# ADC_R_ADC_R_CFG_502C5000h register map
Vendor: Texas Instruments
Peripheral module from a debugger description file (folder AM263P).
Registers are 16-bit, read-only, reset values left out (the file's numbers can be read two ways) unless marked. A register's access mark holds for its fields unless they carry their own. Offsets are as the file gives them; lines under a group give offsets from that group; [hi:lo] are bit positions; {n}, {i} and the like mark numbered series; 'fields as' and 'values as' point back to an identical list; <NAME> marks a mode.

## ADC_R_CFG (part 1 of 2)
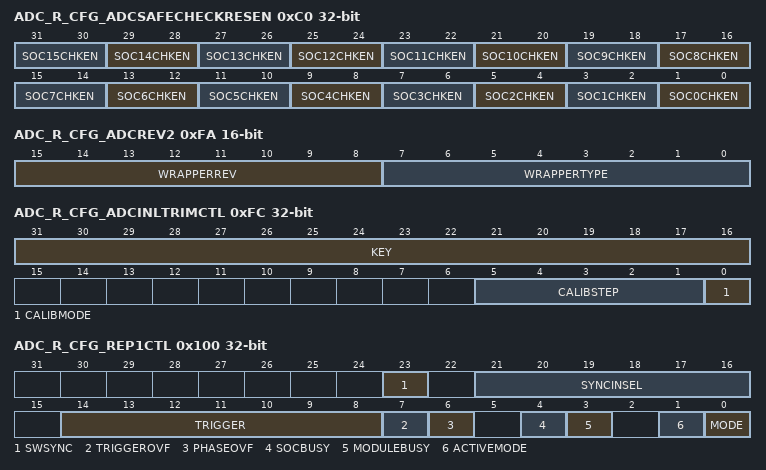
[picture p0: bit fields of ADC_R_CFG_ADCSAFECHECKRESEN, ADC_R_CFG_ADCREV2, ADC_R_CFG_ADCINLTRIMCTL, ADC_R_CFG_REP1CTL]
0xC0 ADC_R_CFG_ADCSAFECHECKRESEN 32-bit rw — ADC Safe Check Result Enable Register.
  [2n+1:2n] SOC{n}CHKEN (n=0..15) — Determine which result will be passed to the safety result checker. Only one of the raw ADC result, the PPB result, or the final PPB accumulated SUM can be passed on to the checker for each conversion. 00 No result passed to safety checker 01 ADCRESULT{n} passed to safety checker 10 PPB Result associated with SOC{n} passed to safety checker 11 PPB Sum associated with SOC{n} passed to safety chekcer Note: if multiple PPBs point to the same SOC, the highest numbered PPB will have priority to pass its result to the safety checker
0xDE ADC_R_CFG_ADCINTCYCLE rw — ADC Early Interrupt Generation Cycle.
  [15:0] DELAY — ADC Early Interrupt Generation Cycle Delay: Defines the delay from the fall edge of ADCSOC in terms of system clock cycles, for the interrupt to be generated.
0xFA ADC_R_CFG_ADCREV2 — ADC Wrapper Revision Register.
  [15:8] WRAPPERREV — ADC Revision. To allow documentation of differences between revisions. First version is labeled as00h
  [7:0] WRAPPERTYPE — ADC Wrapper Type. Always set to 4 for this ADC.
0xFC ADC_R_CFG_ADCINLTRIMCTL 32-bit rw — ADC Linearity Trim Control Register.
  [31:16] KEY — ADC Linearity Trim Control Write Key. Any write to this register must contain the value 0xA5A5 in these bit locations. If a write request attempts to load any other value into these bits, the write for the entire register is ignored. These bits always read back a zero.
  [5:1] CALIBSTEP — ADC Linearity Calibration Step. Defines which of the 24 steps of calibration is to be executed. Never set this bit field while the ADC SELFTRIM is in progress. The R-M-W operation could unintentionally set the CALIBMODE bit again.
  [0] CALIBMODE — ADC Linearity Calibration Mode.
0x100 ADC_R_CFG_REP1CTL 32-bit access not given — ADC Trigger Repeater 1 Control Register.
  [23] SWSYNC — Trigger repeater 1 software force sync. On a sync. event, all registers in repeater 1 are reset to a ready and waiting state. Values of NSEL, PHASE, and MODE are preserved. Note: SOCs associated with repeater 1 are not cleared. (access R/W1TS)
  [21:16] SYNCINSEL rw — Trigger repeater 1 sync. input select. On a sync. event, all registers in repeater 1 are reset to a ready and waiting state. Values of NSEL, PHASE, and MODE are preserved. Note: SOCs associated with repeater 1 are not cleared.
  [14:8] TRIGGER rw — ADC Trigger Repeater 1 Trigger Select. Selects the trigger to modify via oversampling or undersampling. 00h REPTRIG0 - Software only 01h REPTRIG1 - RTI0 Timer 02h REPTRIG2 - RTI1 Timer 03h REPTRIG3 - RTI2 Timer 04h REPTRIG4 - RTI3 Timer 05h REPTRIG5 - InputXBAR.Out[5] 06h REPTRIG6 - spare 07h REPTRIG7 - spare 08h REPTRIG8 - EPWM0, ADCSOCA 09h REPTRIG9 - EPWM0, ADCSOCB 0Ah REPTRIG10 - EPWM1, ADCSOCA 0Bh REPTRIG11 - EPWM1, ADCSOCB 0Ch REPTRIG12 - EPWM2, ADCSOCA 0Dh REPTRIG13 - EPWM2, ADCSOCB 0Eh REPTRIG14 - EPWM3, ADCSOCA 0Fh REPTRIG15 - EPWM3, ADCSOCB .... EPWM4 to EPWM27 40h REPTRIG64 - EPWM28, ADCSOCA 41h REPTRIG65 - EPWM28, ADCSOCB 42h REPTRIG66 - EPWM29, ADCSOCA 43h REPTRIG67 - EPWM29, ADCSOCB 44h REPTRIG68 - EPWM30, ADCSOCA 45h REPTRIG69 - EPWM30, ADCSOCB 46h REPTRIG70 - EPWM31, ADCSOCA 47h REPTRIG71 - EPWM31, ADCSOCB 48h REPTRIG72 - ECAP0, TRIGOUT .... ECAP1 to ECAP8 51h REPTRIG81 - ECAP9, TRIGOUT 52h REPTRIG82 - ECAP10, TRIGOUT .... 57h REPTRIG73 - ECAP15, TRIGOUT 58h REPTRIG1 - RTI4 Timer 59h REPTRIG1 - RTI5 Timer 5Ah REPTRIG1 - RTI6 Timer 5Bh REPTRIG1 - RTI7 Timer .... 7Fh - Reserved
  [7] TRIGGEROVF — ADC Trigger Repeater 1 Oversampled Trigger Overflow. Indicates that a trigger was dropped because a trigger arrived while the repeater was still generating repeated oversampled triggers [NCOUNT was not 0 or SOCs associated with Repeater 1 were still pending]. Writing a 1 will clear this flag. Note: This flag won't be set in undersampling mode or when NSEL = 0; if a trigger arrives before the previous SOCs have completed, the trigger will be passed and the overflow flags of the SOCs that were still pending will be set. Note: If software sets the clear bit on the same cycle that hardware is trying to set the flag bit, then hardware has priority and the overflow bit will not be set (access R/W1TC)
  [6] PHASEOVF — ADC Trigger Repeater 1 Phase Delay Overflow. Indicates that a trigger was dropped because a trigger arrived when the phase delay logic was still waiting to send the delayed trigger [PHASECOUNT was not 0]. Writing a 1 will clear this flag. Note: If software sets the clear bit on the same cycle that hardware is trying to set the flag bit, then hardware has priority and the overflow bit will not be set (access R/W1TC)
  [4] SOCBUSY ro — ADC Trigger Repeater 1 Associated SOCs Busy indicator. In oversampling mode: 0 = no SOCs associated with this repeater are pending 1 = SOCs associated with this repeater are still pending The next repeated trigger to the ADC in oversampling mode will not occur until SPREADCOUNT is 0 [minimum time is complete] and REP1CTL.BUSY = 0 [SOCs associated with trigger repeater 1 are no longer pending]. Note: If the ADC is in burstmode and the BURSTTRIG is Repeater 1, then all round-robin SOCs are considered associated with this repeater and the repeater will not re-trigger until there are no pending round-robin SOCs [in addition to any associated pending high-priority SOCs].
  [3] MODULEBUSY ro — ADC Trigger Repeater 1 Module Busy indicator. In oversampling mode: 0 = Repeater 1 is idle and can accept a new repeated trigger in oversampling mode 1 = Repeater 1 still has repeated triggers remaining [NCOUNT ' 0] or associated SOCs are still pending [SOCBUSY is 1] If a new oversampled trigger is received while the module is still busy, the TRIGGEROVF bit will be set and the trigger will be ignored.
  [1] ACTIVEMODE ro — When a trigger is recived in oversampling or undersampling mode the value of MODE is copied to ACTIVEMODE. ACTIVEMODE determines if the repeater will repeat of filter triggers. Changes to MODE while the repeater is working therefore won't cause any changes in functionality until the module becomes idle and then a new trigger is received. 0 = module is oversampling 1 = module is undersampling
  [0] MODE rw — ADC trigger repeater 1 mode selection. Select either oversampling or undersampling mode. In oversampling mode, when the trigger selected by REP1CTL.TRIGSEL is received, the repeater will repeat the trigger REP1N.NSEL + 1 times. In undersampling mode, when the trigger selected by REP1CTL.TRIGSEL is received the first time, the repeater will pass the trigger through. The next REP1N.NSEL triggers will be ignored. 0 = oversampling 1 = undersampling
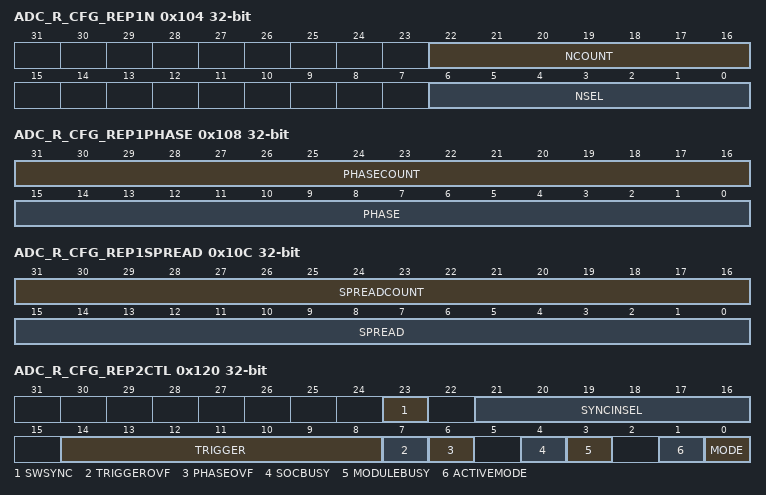
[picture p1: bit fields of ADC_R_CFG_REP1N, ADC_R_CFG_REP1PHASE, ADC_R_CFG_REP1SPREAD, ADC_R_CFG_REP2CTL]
0x104 ADC_R_CFG_REP1N 32-bit access per field — ADC Trigger Repeater 1 N Select Register.
  [22:16] NCOUNT ro — ADC trigger repeater 1 trigger count. In oversampling mode, indicates the number of triggers remaining to be generated. If a trigger is received corresponding to REP1CTL.TRIGSEL while NCOUNT is not 0 [the repeater is still busy generating the repeated triggers] then the trigger will be ignored and REP1CTL.TRIGOVF will be set to 1. In undersampling mode, indicates the number of triggers remaining to be supressed.
  [6:0] NSEL rw — ADC Trigger Repeater 1 selection of number of triggers. In oversampling mode, selects the number of repeated triggers. For each trigger received corresponding to REP1CTL.TRIGSEL, NSEL + 1 triggers will be generated. 0 = 1 trigger is generated [pass-through] 1 = 2 triggers are generated 2 = 3 triggers are generated ... 127 = 128 triggers are generated In undersampling mode, selects the number triggers to be supressed. 1 out NSEL + 1 triggers received corresponding to REP1CTL.TRIGSEL will be passed through [the first trigger will be passed through and the subsequent NSEL triggers will be supressed]. 0 = all triggers are passed 1 = 1 out of 2 triggers are passed 2 = 1 out of 3 triggers are passed ... 127 = 1 out of 128 triggers are passed
0x108 ADC_R_CFG_REP1PHASE 32-bit access per field — ADC Trigger Repeater 1 Phase Select Register.
  [31:16] PHASECOUNT ro — ADC trigger repeater 1 phase delay status. When the trigger selected by REP1CTL.TRIGSEL is received, this register will start counting down from PHASECOUNT until the counter reaches 0, at which point the trigger will be passed on to the repeater re-trigger logic. If the trigger selected by REP1CTL.TRIGSEL is recieved when PHASECOUNT is not 0 [the phase delay logic is busy from the previous trigger] then the new trigger will be ignored and REP1CTL.PHASEOVF will be set to 1.
  [15:0] PHASE rw — ADC trigger repeater 1 phase delay configuration. Defines the number of SYSCLKs to delay the selected trigger before passing it on to the re-triggering logic. 0 = trigger is passed through without delay 1 = trigger is delayed by 1 SYSCLK 2 = trigger is delayed by 2 SYSCLKs ... 65535 = trigger is delayed by 65535 SYSCLKs
0x10C ADC_R_CFG_REP1SPREAD 32-bit access per field — ADC Trigger Repeater 1 Spread Select Register.
  [31:16] SPREADCOUNT ro — ADC trigger repeater 1 spread status. When a trigger is sent to the ADC in oversampling mode, this register will start counting down from SPREAD until SPREADCOUNT equals 0. The next repeated trigger to the ADC in oversampling mode will not occur until SPREADCOUNT is 0 [minimum time is complete] and REP1CTL.BUSY = 0 [SOCs associated with trigger repeater 1 are no longer pending].
  [15:0] SPREAD rw — ADC trigger repeater 1 spread delay configuration. In oversampling mode, defines the minimum number of SYSCLKs to wait before creating the next repeated trigger to the ADC. If SPREAD is less than the time needed for all SOCs associated with repeater 1 to sample and convert, then the repeater will generate triggers as fast as the ADC can convert the associated conversions. If SPREAD is greater than the time needed for all SOCs associated with repeater 1 to sample and convert, then repeated triggers to the ADC will be SPREAD SYSCLK cycles apart. 0 = oversampled repeated triggers occur as fast as the ADC can sample and convert associated SOCs 1 = time between repeated triggers is at least 1 SYSCLKs 2 = time between repeated triggers is at least 2 SYSCLKs ... 65535 = time between repeated triggers is at least 65535 SYSCLKs
0x110 ADC_R_CFG_REP1FRC access not given — ADC Trigger Repeater 1 Software Force Register.
  [0] SWFRC — Write 1 to force a trigger to repeat block 1 input regardless of the value of TRIGGER. Always reads 0. (access R/W1TS)
0x120 ADC_R_CFG_REP2CTL 32-bit access not given — ADC Trigger Repeater 2 Control Register.
  [23] SWSYNC — Trigger repeater 2 software force sync. On a sync. event, all registers in repeater 2 are reset to a ready and waiting state. Values of NSEL, PHASE, and MODE are preserved. Note: SOCs associated with repeater 2 are not cleared. (access R/W1TS)
  [21:16] SYNCINSEL rw — Trigger repeater 2 sync. input select. On a sync. event, all registers in repeater 2 are reset to a ready and waiting state. Values of NSEL, PHASE, and MODE are preserved. Note: SOCs associated with repeater 2 are not cleared.
  [14:8] TRIGGER rw — ADC Trigger Repeater 2 Trigger Select. Selects the trigger to modify via oversampling or undersampling. 00h REPTRIG0 - Software only 01h REPTRIG1 - RTI0 Timer 02h REPTRIG2 - RTI1 Timer 03h REPTRIG3 - RTI2 Timer 04h REPTRIG4 - RTI3 Timer 05h REPTRIG5 - InputXBAR.Out[5] 06h REPTRIG6 - spare 07h REPTRIG7 - spare 08h REPTRIG8 - EPWM0, ADCSOCA 09h REPTRIG9 - EPWM0, ADCSOCB 0Ah REPTRIG10 - EPWM1, ADCSOCA 0Bh REPTRIG11 - EPWM1, ADCSOCB 0Ch REPTRIG12 - EPWM2, ADCSOCA 0Dh REPTRIG13 - EPWM2, ADCSOCB 0Eh REPTRIG14 - EPWM3, ADCSOCA 0Fh REPTRIG15 - EPWM3, ADCSOCB .... EPWM4 to EPWM27 40h REPTRIG64 - EPWM28, ADCSOCA 41h REPTRIG65 - EPWM28, ADCSOCB 42h REPTRIG66 - EPWM29, ADCSOCA 43h REPTRIG67 - EPWM29, ADCSOCB 44h REPTRIG68 - EPWM30, ADCSOCA 45h REPTRIG69 - EPWM30, ADCSOCB 46h REPTRIG70 - EPWM31, ADCSOCA 47h REPTRIG71 - EPWM31, ADCSOCB 48h REPTRIG72 - ECAP0, TRIGOUT .... ECAP1 to ECAP8 51h REPTRIG81 - ECAP9, TRIGOUT 52h REPTRIG82 - ECAP10, TRIGOUT .... 57h REPTRIG73 - ECAP15, TRIGOUT 58h REPTRIG1 - RTI4 Timer 59h REPTRIG1 - RTI5 Timer 5Ah REPTRIG1 - RTI6 Timer 5Bh REPTRIG1 - RTI7 Timer .... 64h- 7Fh - Reserved
  [7] TRIGGEROVF — ADC Trigger Repeater 2 Oversampled Trigger Overflow. Indicates that a trigger was dropped because a trigger arrived while the repeater was still generating repeated oversampled triggers [NCOUNT was not 0 or SOCs associated with Repeater 2 were still pending]. Writing a 1 will clear this flag. Note: This flag won't be set in undersampling mode or when NSEL = 0; if a trigger arrives before the previous SOCs have completed, the trigger will be passed and the overflow flags of the SOCs that were still pending will be set. Note: If software sets the clear bit on the same cycle that hardware is trying to set the flag bit, then hardware has priority and the overflow bit will not be set (access R/W1TC)
  [6] PHASEOVF — ADC Trigger Repeater 2 Phase Delay Overflow. Indicates that a trigger was dropped because a trigger arrived when the phase delay logic was still waiting to send the delayed trigger [PHASECOUNT was not 0]. Writing a 1 will clear this flag. Note: If software sets the clear bit on the same cycle that hardware is trying to set the flag bit, then hardware has priority and the overflow bit will not be set (access R/W1TC)
  [4] SOCBUSY ro — ADC Trigger Repeater 2 Associated SOCs Busy indicator. In oversampling mode: 0 = no SOCs associated with this repeater are pending 1 = SOCs associated with this repeater are still pending The next repeated trigger to the ADC in oversampling mode will not occur until SPREADCOUNT is 0 [minimum time is complete] and REP2CTL.BUSY = 0 [SOCs associated with trigger repeater 2 are no longer pending]. Note: If the ADC is in burstmode and the BURSTTRIG is Repeater 2, then all round-robin SOCs are considered associated with this repeater and the repeater will not re-trigger until there are no pending round-robin SOCs [in addition to any associated pending high-priority SOCs].
  [3] MODULEBUSY ro — ADC Trigger Repeater 2 Module Busy indicator. In oversampling mode: 0 = Repeater 2 is idle and can accept a new repeated trigger in oversampling mode 1 = Repeater 2 still has repeated triggers remaining [NCOUNT ' 0] or associated SOCs are still pending [SOCBUSY is 1] If a new oversampled trigger is received while the module is still busy, the TRIGGEROVF bit will be set and the trigger will be ignored.
  [1] ACTIVEMODE ro — When a trigger is recived in oversampling or undersampling mode the value of MODE is copied to ACTIVEMODE. ACTIVEMODE determines if the repeater will repeat of filter triggers. Changes to MODE while the repeater is working therefore won't cause any changes in functionality until the module becomes idle and then a new trigger is received. 0 = module is oversampling 1 = module is undersampling
  [0] MODE rw — ADC trigger repeater 2 mode selection. Select either oversampling or undersampling mode. In oversampling mode, when the trigger selected by REP2CTL.TRIGSEL is received, the repeater will repeat the trigger REP2N.NSEL + 1 times. In undersampling mode, when the trigger selected by REP2CTL.TRIGSEL is received the first time, the repeater will pass the trigger through. The next REP2N.NSEL triggers will be ignored. 0 = oversampling 1 = undersampling
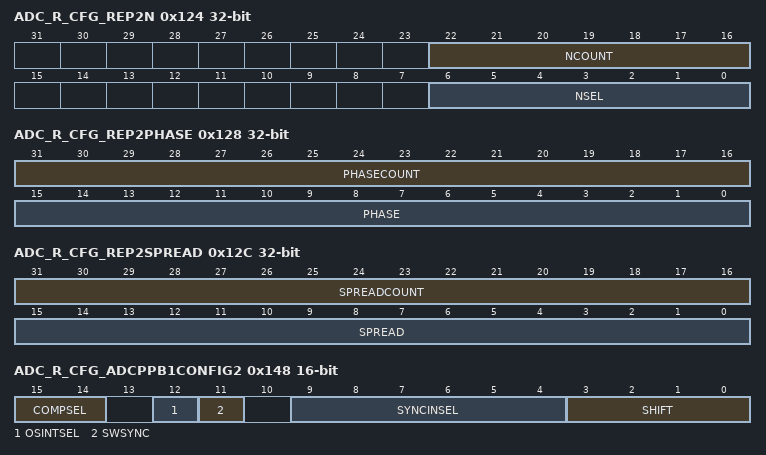
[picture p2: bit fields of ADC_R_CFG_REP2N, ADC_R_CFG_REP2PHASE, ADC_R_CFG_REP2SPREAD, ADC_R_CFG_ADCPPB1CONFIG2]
0x124 ADC_R_CFG_REP2N 32-bit access per field — ADC Trigger Repeater 2 N Select Register.
  [22:16] NCOUNT ro — ADC trigger repeater 2 trigger count. In oversampling mode, indicates the number of triggers remaining to be generated. If a trigger is received corresponding to REP2CTL.TRIGSEL while NCOUNT is not 0 [the repeater is still busy generating the repeated triggers] then the trigger will be ignored and REP2CTL.TRIGOVF will be set to 1. In undersampling mode, indicates the number of triggers remaining to be supressed.
  [6:0] NSEL rw — ADC Trigger Repeater 2 selection of number of triggers. In oversampling mode, selects the number of repeated triggers. For each trigger received corresponding to REP2CTL.TRIGSEL, NSEL + 1 triggers will be generated. 0 = 1 trigger is generated [pass-through] 1 = 2 triggers are generated 2 = 3 triggers are generated ... 127 = 128 triggers are generated In undersampling mode, selects the number triggers to be supressed. 1 out NSEL + 1 triggers received corresponding to REP2CTL.TRIGSEL will be passed through [the first trigger will be passed through and the subsequent NSEL triggers will be supressed]. 0 = all triggers are passed 1 = 1 out of 2 triggers are passed 2 = 1 out of 3 triggers are passed ... 127 = 1 out of 128 triggers are passed
0x128 ADC_R_CFG_REP2PHASE 32-bit access per field — ADC Trigger Repeater 2 Phase Select Register.
  [31:16] PHASECOUNT ro — ADC trigger repeater 2 phase delay status. When the trigger selected by REP2CTL.TRIGSEL is received, this register will start counting down from PHASECOUNT until the counter reaches 0, at which point the trigger will be passed on to the repeater re-trigger logic. If the trigger selected by REP2CTL.TRIGSEL is recieved when PHASECOUNT is not 0 [the phase delay logic is busy from the previous trigger] then the new trigger will be ignored and REP2CTL.PHASEOVF will be set to 1.
  [15:0] PHASE rw — ADC trigger repeater 2 phase delay configuration. Defines the number of SYSCLKs to delay the selected trigger before passing it on to the re-triggering logic. 0 = trigger is passed through without delay 1 = trigger is delayed by 1 SYSCLK 2 = trigger is delayed by 2 SYSCLKs ... 65535 = trigger is delayed by 65535 SYSCLKs
0x12C ADC_R_CFG_REP2SPREAD 32-bit access per field — ADC Trigger Repeater 2 Spread Select Register.
  [31:16] SPREADCOUNT ro — ADC trigger repeater 2 spread status. When a trigger is sent to the ADC in oversampling mode, this register will start counting down from SPREAD until SPREADCOUNT equals 0. The next repeated trigger to the ADC in oversampling mode will not occur until SPREADCOUNT is 0 [minimum time is complete] and REP2CTL.BUSY = 0 [SOCs associated with trigger repeater 2 are no longer pending].
  [15:0] SPREAD rw — ADC trigger repeater 2 spread delay configuration. In oversampling mode, defines the minimum number of SYSCLKs to wait before creating the next repeated trigger to the ADC. If SPREAD is less than the time needed for all SOCs associated with repeater 2 to sample and convert, then the repeater will generate triggers as fast as the ADC can convert the associated conversions. If SPREAD is greater than the time needed for all SOCs associated with repeater 2 to sample and convert, then repeated triggers to the ADC will be SPREAD SYSCLK cycles apart. 0 = oversampled repeated triggers occur as fast as the ADC can sample and convert associated SOCs 1 = time between repeated triggers is at least 1 SYSCLKs 2 = time between repeated triggers is at least 2 SYSCLKs ... 65535 = time between repeated triggers is at least 65535 SYSCLKs
0x130 ADC_R_CFG_REP2FRC access not given — ADC Trigger Repeater 2 Software Force Register.
  [0] SWFRC — Write 1 to force a trigger to repeat block 2 input regardless of the value of TRIGGER. Always reads 0. (access R/W1TS)
{0x10C+0x34*i} ADC_R_CFG_ADCPPB{i}LIMIT rw (i=1..4) — ADC PPB{i}Conversion Count Limit Register.
  [9:0] LIMIT — Post Processing Block {i} Oversampling Limit. Defines the number of conversions to accumulate before PSUM is automatically loaded into SUM. To prevent PSUM from overflowing, do not write a value larger than 128 when the ADC is operating in 16-bit mode.
0x144 ADC_R_CFG_ADCPPBP1PCOUNT — ADC PPB1 Partial Conversion Count Register.
  [9:0] PCOUNT — Post Processing Block 1 Oversampling Partial Count. Each time a new result propagates through the PPB signal chain and accumulates into ADCPPB1PSUM this register is incremented by 1. This register is reset when either a count-match event occurs [PCOUNT = LIMIT] or PPB1 receives a sync. event. This result is available 1 SYSCLK cycle after the associated ADCPPB1RESULT is available. This will be 2 SYSCLK cycles after the associated ADCRESULT is available, unless multiple PPBs point to the same SOC [refer to the ADCPPB1RESULT timing information].
0x148 ADC_R_CFG_ADCPPB1CONFIG2 access not given — ADC PPB1 Sum Shift Register.
  [15:14] COMPSEL rw — Post Processing Block 1 Compare Source Select. This field determines whether ADCPPB1RESULT, ADCPPB1PSUM, or ADCPPB1SUM is used for the zero-crossing detect logic and threshold compare. 00 = ADCPPB1RESULT is used for compare logic 01 = ADCPPB1PSUM is used for compare logic 10 = ADCPPB1SUM is used for compare logic 11 = Reserved Note: when ADCPPB1PSUM is selected as the compare source and when a LIMIT match occurs [ADCPPB1LIMIT equals ADCPPB1COUNT] the ADCPPB1PSUM register will be cleared and the final sum will be loaded into ADCPPB1SUM. For this sample, the final sum, ADCPPB1SUM will be used for the compariosn instead of ADCPPB1PSUM.
  [12] OSINTSEL rw — Post Processing Block 1 Interrupt Source Select. OSINT1 can be used to trigger an ADC interrupt [ADCINT1 through ADCINT4] via selection in the ADCINT1N2 or ADCINT3N4. This selection determines if a sync. event can trigger OSINT1 in addition to a PCOUNT = LIMIT event. 0 = OSINT1 will be generated from PCOUNT = LIMIT only 1 = OSTIN1 will be generated form PCOUNT = LIMIT or a sync. event. Note: If a SYNC event would cause an OSINT one cycle after OSINT would have been cause by PCOUNT = LIMIT match, then the second OSINT is ignored.
  [11] SWSYNC — PPB 1 software force sync. On a sync. event, all partial registers transfer to the final registers and are then reset. Note: In the case where the software force occurs at the same time that a new sample is added to the PSUM and the PSUM is being used for a high or low limit compare, then the comparison will not occur. (access R/W1TS)
  [9:4] SYNCINSEL rw — PPB 1 sync. input select. On a sync. event, all partial registers transfer to the final registers and are then reset. Refer to SOC spec for details
  [3:0] SHIFT rw — Post Processing Block 1 right shift. Defines the number of bits to right shift PSUM before loading into the final SUM. 0 : no right shift 1 : SUM = PSUM '' 1 2 : SUM = PSUM '' 2 ... 10 : SUM = PSUM '' 10 11 -15 : Reserved
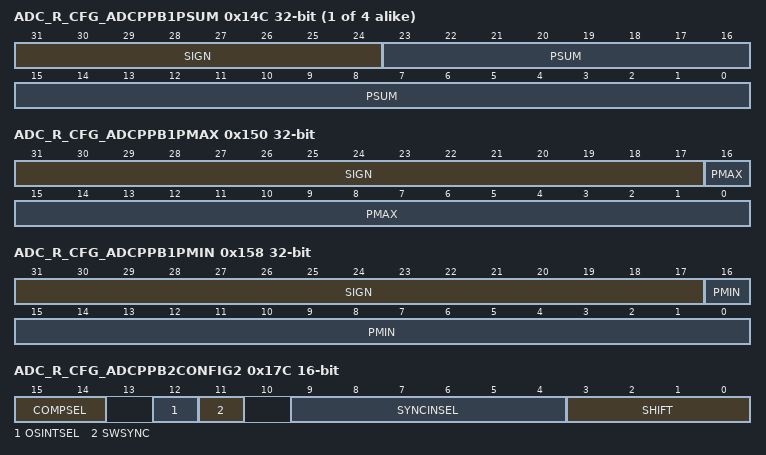
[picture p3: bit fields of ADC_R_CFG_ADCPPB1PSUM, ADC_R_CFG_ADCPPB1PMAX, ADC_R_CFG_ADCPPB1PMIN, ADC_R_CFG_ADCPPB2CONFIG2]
{0x118+0x34*i} ADC_R_CFG_ADCPPB{i}PSUM 32-bit (i=1..4) — ADC PPB{i} Partial Sum Register.
  [31:24] SIGN — Sign Extended Bits. These bits reflect the same value as bit 23.
  [23:0] PSUM — Post Processing Block {i} Oversampling Partial Sum. Each time a new result propagates through the PPB signal chain and latches into ADCPPB{i}RESULT the result is subsequently accumulated into this register. This register is reset when either a count-match event occurs [PCOUNT = LIMIT] or PPB{i} receives a sync. event. This result is available 1 SYSCLK cycle after the associated ADCPPB{i}RESULT is available. This will be 2 SYSCLK cycles after the associated ADCRESULT is available, unless multiple PPBs point to the same SOC. In the case of multiple PPBs associated with the same SOC, the lowest numbered PPB's result will be availble 2 SYSCLK cycle after the associated ADCRESULT and subsequent results [in order from lowest numbered PPB to highest] will each become available every 2-3 SYSCLK cycles [refer to the TRM for detailed timing information].
0x150 ADC_R_CFG_ADCPPB1PMAX 32-bit — ADC PPB1 Partial Max Register.
  [31:17] SIGN — Sign Extended Bits. These bits reflect the same value as bit 16.
  [16:0] PMAX — Post Processing Block 1 Oversampling Partial Max. Each time a new result propagates through the PPB signal chain and latches into ADCPPB1RESULT the result replaces this register if it is larger. This register is reset when either a count-match event occurs [PCOUNT = LIMIT] or PPB1 receives a sync. event. This result is available 1 SYSCLK cycle after the associated ADCPPB1RESULT is available. This will be 2 SYSCLK cycles after the associated ADCRESULT is available, unless multiple PPBs point to the same SOC [refer to the ADCPPB1RESULT timing information].
0x154 ADC_R_CFG_ADCPPB1PMAXI — ADC PPB1 Partial Max Index Register.
  [9:0] PMAXI — Post Processing Block 1 Oversampling Partial Index of Max. Each time a new result propagates through the PPB signal chain and latches into ADCPPB1RESULT if the result replaces PMAX this register is loaded with the current value of PCOUNT. This register is reset when either a count-match event occurs [PCOUNT = LIMIT] or PPB1 receives a sync. event. This result is available 1 SYSCLK cycle after the associated ADCPPB1RESULT is available. This will be 2 SYSCLK cycles after the associated ADCRESULT is available, unless multiple PPBs point to the same SOC [refer to the ADCPPB1RESULT timing information].
0x158 ADC_R_CFG_ADCPPB1PMIN 32-bit — ADC PPB1 Partial MIN Register.
  [31:17] SIGN — Sign Extended Bits. These bits reflect the same value as bit 16.
  [16:0] PMIN — Post Processing Block 1 Oversampling Partial Min. Each time a new result propagates through the PPB signal chain and latches into ADCPPB1RESULT the result replaces this register if it is smaller. This register is reset when either a count-match event occurs [PCOUNT = LIMIT] or PPB1 receives a sync. event. This result is available 1 SYSCLK cycle after the associated ADCPPB1RESULT is available. This will be 2 SYSCLK cycles after the associated ADCRESULT is available, unless multiple PPBs point to the same SOC [refer to the ADCPPB1RESULT timing information].
0x15C ADC_R_CFG_ADCPPB1PMINI — ADC PPB1 Partial Min Index Register.
  [9:0] PMINI — Post Processing Block 1 Oversampling Partial Index of Min. Each time a new result propagates through the PPB signal chain and latches into ADCPPB1RESULT if the result replaces PMIN this register is loaded with the current value of PCOUNT. This register is reset when either a count-match event occurs [PCOUNT = LIMIT] or PPB1 receives a sync. event. This result is available 1 SYSCLK cycle after the associated ADCPPB1RESULT is available. This will be 2 SYSCLK cycles after the associated ADCRESULT is available, unless multiple PPBs point to the same SOC [refer to the ADCPPB1RESULT timing information].
{0x12C+0x34*i} ADC_R_CFG_ADCPPB{i}TRIPLO2 32-bit rw (i=1..4) — ADC PPB{i} Extended Trip Low Register.
  [23:0] LIMITLO — ADC Post Processing Block {i} Trip High Low Limit. This value sets the digital comparator trip low limit if ADCPPB{i}TRIPLO.LIMITLO2EN = 1. When comparing to an ADCPPBxRESULT register, the upper bits will be ignored: - TRIPLO2[23:17] will be ignored in 16 bit mode - TRIPLO2[23:13] will be ignored in 12 bit mode
0x178 ADC_R_CFG_ADCPPBP2PCOUNT — ADC PPB2 Partial Conversion Count Register.
  [9:0] PCOUNT — Post Processing Block 2 Oversampling Partial Count. Each time a new result propagates through the PPB signal chain and accumulates into ADCPPB2PSUM this register is incremented by 1. This register is reset when either a count-match event occurs [PCOUNT = LIMIT] or PPB2 receives a sync. event. This result is available 1 SYSCLK cycle after the associated ADCPPB2RESULT is available. This will be 2 SYSCLK cycles after the associated ADCRESULT is available, unless multiple PPBs point to the same SOC [refer to the ADCPPB2RESULT timing information].
0x17C ADC_R_CFG_ADCPPB2CONFIG2 access not given — ADC PPB2 Sum Shift Register.
  [15:14] COMPSEL rw — Post Processing Block 2 Compare Source Select. This field determines whether ADCPPB2RESULT, ADCPPB2PSUM, or ADCPPB2SUM is used for the zero-crossing detect logic and threshold compare. 00 = ADCPPB2RESULT is used for compare logic 01 = ADCPPB2PSUM is used for compare logic 10 = ADCPPB2SUM is used for compare logic 11 = Reserved Note: when ADCPPB2PSUM is selected as the compare source and when a LIMIT match occurs [ADCPPB2LIMIT equals ADCPPB2COUNT] the ADCPPB2PSUM register will be cleared and the final sum will be loaded into ADCPPB2SUM. For this sample, the final sum, ADCPPB2SUM will be used for the compariosn instead of ADCPPB2PSUM.
  [12] OSINTSEL rw — Post Processing Block 2 Interrupt Source Select. OSINT2 can be used to trigger an ADC interrupt [ADCINT1 through ADCINT4] via selection in the ADCINT1N2 or ADCINT3N4. This selection determines if a sync. event can trigger OSINT2 in addition to a PCOUNT = LIMIT event. 0 = OSINT2 will be generated from PCOUNT = LIMIT only 1 = OSTIN2 will be generated form PCOUNT = LIMIT or a sync. event. Note: If a SYNC event would cause an OSINT one cycle after OSINT would have been cause by PCOUNT = LIMIT match, then the second OSINT is ignored.
  [11] SWSYNC — PPB 2 software force sync. On a sync. event, all partial registers transfer to the final registers and are then reset. Note: In the case where the software force occurs at the same time that a new sample is added to the PSUM and the PSUM is being used for a high or low limit compare, then the comparison will not occur. (access R/W1TS)
  [9:4] SYNCINSEL rw — PPB 2 sync. input select. On a sync. event, all partial registers transfer to the final registers and are then reset. Refer to SOC spec for details
  [3:0] SHIFT rw — Post Processing Block 2 right shift. Defines the number of bits to right shift PSUM before loading into the final SUM. 0 : no right shift 1 : SUM = PSUM '' 1 2 : SUM = PSUM '' 2 ... 10 : SUM = PSUM '' 10 11 -15 : Reserved
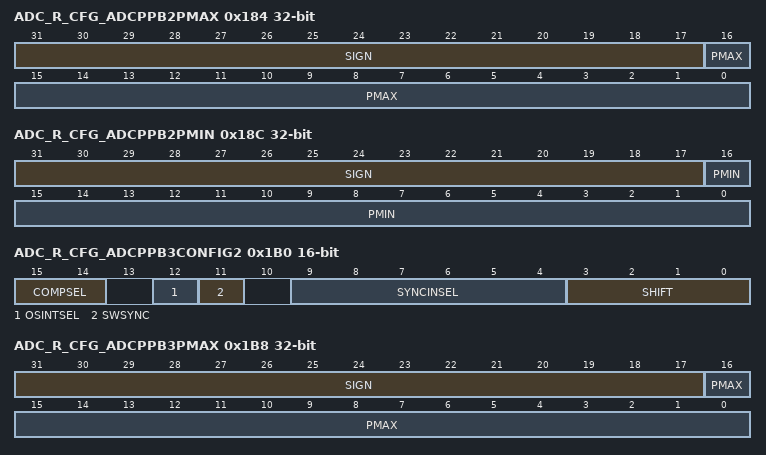
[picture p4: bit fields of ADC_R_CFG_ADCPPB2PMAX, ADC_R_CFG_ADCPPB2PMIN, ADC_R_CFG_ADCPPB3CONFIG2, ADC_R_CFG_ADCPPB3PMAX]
0x184 ADC_R_CFG_ADCPPB2PMAX 32-bit — ADC PPB2 Partial Max Register.
  [31:17] SIGN — Sign Extended Bits. These bits reflect the same value as bit 16.
  [16:0] PMAX — Post Processing Block 2 Oversampling Partial Max. Each time a new result propagates through the PPB signal chain and latches into ADCPPB2RESULT the result replaces this register if it is larger. This register is reset when either a count-match event occurs [PCOUNT = LIMIT] or PPB2 receives a sync. event. This result is available 1 SYSCLK cycle after the associated ADCPPB2RESULT is available. This will be 2 SYSCLK cycles after the associated ADCRESULT is available, unless multiple PPBs point to the same SOC [refer to the ADCPPB2RESULT timing information].
0x188 ADC_R_CFG_ADCPPB2PMAXI — ADC PPB2 Partial Max Index Register.
  [9:0] PMAXI — Post Processing Block 2 Oversampling Partial Index of Max. Each time a new result propagates through the PPB signal chain and latches into ADCPPB2RESULT if the result replaces PMAX this register is loaded with the current value of PCOUNT. This register is reset when either a count-match event occurs [PCOUNT = LIMIT] or PPB2 receives a sync. event. This result is available 1 SYSCLK cycle after the associated ADCPPB2RESULT is available. This will be 2 SYSCLK cycles after the associated ADCRESULT is available, unless multiple PPBs point to the same SOC [refer to the ADCPPB2RESULT timing information].
0x18C ADC_R_CFG_ADCPPB2PMIN 32-bit — ADC PPB2 Partial MIN Register.
  [31:17] SIGN — Sign Extended Bits. These bits reflect the same value as bit 16.
  [16:0] PMIN — Post Processing Block 2 Oversampling Partial Min. Each time a new result propagates through the PPB signal chain and latches into ADCPPB2RESULT the result replaces this register if it is smaller. This register is reset when either a count-match event occurs [PCOUNT = LIMIT] or PPB2 receives a sync. event. This result is available 1 SYSCLK cycle after the associated ADCPPB2RESULT is available. This will be 2 SYSCLK cycles after the associated ADCRESULT is available, unless multiple PPBs point to the same SOC [refer to the ADCPPB2RESULT timing information].
0x190 ADC_R_CFG_ADCPPB2PMINI — ADC PPB2 Partial Min Index Register.
  [9:0] PMINI — Post Processing Block 2 Oversampling Partial Index of Min. Each time a new result propagates through the PPB signal chain and latches into ADCPPB2RESULT if the result replaces PMIN this register is loaded with the current value of PCOUNT. This register is reset when either a count-match event occurs [PCOUNT = LIMIT] or PPB2 receives a sync. event. This result is available 1 SYSCLK cycle after the associated ADCPPB2RESULT is available. This will be 2 SYSCLK cycles after the associated ADCRESULT is available, unless multiple PPBs point to the same SOC [refer to the ADCPPB2RESULT timing information].
0x1AC ADC_R_CFG_ADCPPBP3PCOUNT — ADC PPB3 Partial Conversion Count Register.
  [9:0] PCOUNT — Post Processing Block 3 Oversampling Partial Count. Each time a new result propagates through the PPB signal chain and accumulates into ADCPPB3PSUM this register is incremented by 1. This register is reset when either a count-match event occurs [PCOUNT = LIMIT] or PPB3 receives a sync. event. This result is available 1 SYSCLK cycle after the associated ADCPPB3RESULT is available. This will be 2 SYSCLK cycles after the associated ADCRESULT is available, unless multiple PPBs point to the same SOC [refer to the ADCPPB3RESULT timing information].
0x1B0 ADC_R_CFG_ADCPPB3CONFIG2 access not given — ADC PPB3 Sum Shift Register.
  [15:14] COMPSEL rw — Post Processing Block 3 Compare Source Select. This field determines whether ADCPPB3RESULT, ADCPPB3PSUM, or ADCPPB3SUM is used for the zero-crossing detect logic and threshold compare. 00 = ADCPPB3RESULT is used for compare logic 01 = ADCPPB3PSUM is used for compare logic 10 = ADCPPB3SUM is used for compare logic 11 = Reserved Note: when ADCPPB3PSUM is selected as the compare source and when a LIMIT match occurs [ADCPPB3LIMIT equals ADCPPB3COUNT] the ADCPPB3PSUM register will be cleared and the final sum will be loaded into ADCPPB3SUM. For this sample, the final sum, ADCPPB3SUM will be used for the compariosn instead of ADCPPB3PSUM.
  [12] OSINTSEL rw — Post Processing Block 3 Interrupt Source Select. OSINT3 can be used to trigger an ADC interrupt [ADCINT1 through ADCINT4] via selection in the ADCINT1N2 or ADCINT3N4. This selection determines if a sync. event can trigger OSINT3 in addition to a PCOUNT = LIMIT event. 0 = OSINT3 will be generated from PCOUNT = LIMIT only 1 = OSTIN3 will be generated form PCOUNT = LIMIT or a sync. event. Note: If a SYNC event would cause an OSINT one cycle after OSINT would have been cause by PCOUNT = LIMIT match, then the second OSINT is ignored.
  [11] SWSYNC — PPB 3 software force sync. On a sync. event, all partial registers transfer to the final registers and are then reset. Note: In the case where the software force occurs at the same time that a new sample is added to the PSUM and the PSUM is being used for a high or low limit compare, then the comparison will not occur. (access R/W1TS)
  [9:4] SYNCINSEL rw — PPB 3 sync. input select. On a sync. event, all partial registers transfer to the final registers and are then reset. Refer to SOC spec for details
  [3:0] SHIFT rw — Post Processing Block 3 right shift. Defines the number of bits to right shift PSUM before loading into the final SUM. 0 : no right shift 1 : SUM = PSUM '' 1 2 : SUM = PSUM '' 2 ... 10 : SUM = PSUM '' 10 11 -15 : Reserved
0x1B8 ADC_R_CFG_ADCPPB3PMAX 32-bit — ADC PPB3 Partial Max Register.
  [31:17] SIGN — Sign Extended Bits. These bits reflect the same value as bit 16.
  [16:0] PMAX — Post Processing Block 3 Oversampling Partial Max. Each time a new result propagates through the PPB signal chain and latches into ADCPPB3RESULT the result replaces this register if it is larger. This register is reset when either a count-match event occurs [PCOUNT = LIMIT] or PPB3 receives a sync. event. This result is available 1 SYSCLK cycle after the associated ADCPPB3RESULT is available. This will be 2 SYSCLK cycles after the associated ADCRESULT is available, unless multiple PPBs point to the same SOC [refer to the ADCPPB3RESULT timing information].
0x1BC ADC_R_CFG_ADCPPB3PMAXI — ADC PPB3 Partial Max Index Register.
  [9:0] PMAXI — Post Processing Block 3 Oversampling Partial Index of Max. Each time a new result propagates through the PPB signal chain and latches into ADCPPB3RESULT if the result replaces PMAX this register is loaded with the current value of PCOUNT. This register is reset when either a count-match event occurs [PCOUNT = LIMIT] or PPB3 receives a sync. event. This result is available 1 SYSCLK cycle after the associated ADCPPB3RESULT is available. This will be 2 SYSCLK cycles after the associated ADCRESULT is available, unless multiple PPBs point to the same SOC [refer to the ADCPPB3RESULT timing information].
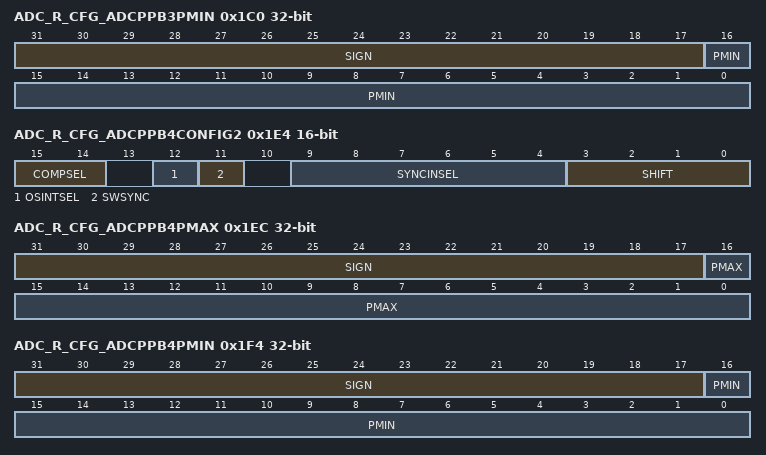
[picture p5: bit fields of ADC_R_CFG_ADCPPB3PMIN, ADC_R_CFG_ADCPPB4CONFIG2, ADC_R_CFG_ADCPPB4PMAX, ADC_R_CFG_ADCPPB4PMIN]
0x1C0 ADC_R_CFG_ADCPPB3PMIN 32-bit — ADC PPB3 Partial MIN Register.
  [31:17] SIGN — Sign Extended Bits. These bits reflect the same value as bit 16.
  [16:0] PMIN — Post Processing Block 3 Oversampling Partial Min. Each time a new result propagates through the PPB signal chain and latches into ADCPPB3RESULT the result replaces this register if it is smaller. This register is reset when either a count-match event occurs [PCOUNT = LIMIT] or PPB3 receives a sync. event. This result is available 1 SYSCLK cycle after the associated ADCPPB3RESULT is available. This will be 2 SYSCLK cycles after the associated ADCRESULT is available, unless multiple PPBs point to the same SOC [refer to the ADCPPB3RESULT timing information].
0x1C4 ADC_R_CFG_ADCPPB3PMINI — ADC PPB3 Partial Min Index Register.
  [9:0] PMINI — Post Processing Block 3 Oversampling Partial Index of Min. Each time a new result propagates through the PPB signal chain and latches into ADCPPB3RESULT if the result replaces PMIN this register is loaded with the current value of PCOUNT. This register is reset when either a count-match event occurs [PCOUNT = LIMIT] or PPB3 receives a sync. event. This result is available 1 SYSCLK cycle after the associated ADCPPB3RESULT is available. This will be 2 SYSCLK cycles after the associated ADCRESULT is available, unless multiple PPBs point to the same SOC [refer to the ADCPPB3RESULT timing information].
0x1E0 ADC_R_CFG_ADCPPBP4PCOUNT — ADC PPB4 Partial Conversion Count Register.
  [9:0] PCOUNT — Post Processing Block 4 Oversampling Partial Count. Each time a new result propagates through the PPB signal chain and accumulates into ADCPPB4PSUM this register is incremented by 1. This register is reset when either a count-match event occurs [PCOUNT = LIMIT] or PPB4 receives a sync. event. This result is available 1 SYSCLK cycle after the associated ADCPPB4RESULT is available. This will be 2 SYSCLK cycles after the associated ADCRESULT is available, unless multiple PPBs point to the same SOC [refer to the ADCPPB4RESULT timing information].
0x1E4 ADC_R_CFG_ADCPPB4CONFIG2 access not given — ADC PPB4 Sum Shift Register.
  [15:14] COMPSEL rw — Post Processing Block 4 Compare Source Select. This field determines whether ADCPPB4RESULT, ADCPPB4PSUM, or ADCPPB4SUM is used for the zero-crossing detect logic and threshold compare. 00 = ADCPPB4RESULT is used for compare logic 01 = ADCPPB4PSUM is used for compare logic 10 = ADCPPB4SUM is used for compare logic 11 = Reserved Note: when ADCPPB4PSUM is selected as the compare source and when a LIMIT match occurs [ADCPPB4LIMIT equals ADCPPB4COUNT] the ADCPPB4PSUM register will be cleared and the final sum will be loaded into ADCPPB4SUM. For this sample, the final sum, ADCPPB4SUM will be used for the compariosn instead of ADCPPB4PSUM.
  [12] OSINTSEL rw — Post Processing Block 4 Interrupt Source Select. OSINT4 can be used to trigger an ADC interrupt [ADCINT1 through ADCINT4] via selection in the ADCINT1N2 or ADCINT3N4. This selection determines if a sync. event can trigger OSINT4 in addition to a PCOUNT = LIMIT event. 0 = OSINT4 will be generated from PCOUNT = LIMIT only 1 = OSTIN4 will be generated form PCOUNT = LIMIT or a sync. event. Note: If a SYNC event would cause an OSINT one cycle after OSINT would have been cause by PCOUNT = LIMIT match, then the second OSINT is ignored.
  [11] SWSYNC — PPB 4 software force sync. On a sync. event, all partial registers transfer to the final registers and are then reset. Note: In the case where the software force occurs at the same time that a new sample is added to the PSUM and the PSUM is being used for a high or low limit compare, then the comparison will not occur. (access R/W1TS)
  [9:4] SYNCINSEL rw — PPB 4 sync. input select. On a sync. event, all partial registers transfer to the final registers and are then reset. Refer to SOC spec for details
  [3:0] SHIFT rw — Post Processing Block 4 right shift. Defines the number of bits to right shift PSUM before loading into the final SUM. 0 : no right shift 1 : SUM = PSUM '' 1 2 : SUM = PSUM '' 2 ... 10 : SUM = PSUM '' 10 11 -15 : Reserved
0x1EC ADC_R_CFG_ADCPPB4PMAX 32-bit — ADC PPB4 Partial Max Register.
  [31:17] SIGN — Sign Extended Bits. These bits reflect the same value as bit 16.
  [16:0] PMAX — Post Processing Block 4 Oversampling Partial Max. Each time a new result propagates through the PPB signal chain and latches into ADCPPB4RESULT the result replaces this register if it is larger. This register is reset when either a count-match event occurs [PCOUNT = LIMIT] or PPB4 receives a sync. event. This result is available 1 SYSCLK cycle after the associated ADCPPB4RESULT is available. This will be 2 SYSCLK cycles after the associated ADCRESULT is available, unless multiple PPBs point to the same SOC [refer to the ADCPPB4RESULT timing information].
0x1F0 ADC_R_CFG_ADCPPB4PMAXI — ADC PPB4 Partial Max Index Register.
  [9:0] PMAXI — Post Processing Block 4 Oversampling Partial Index of Max. Each time a new result propagates through the PPB signal chain and latches into ADCPPB4RESULT if the result replaces PMAX this register is loaded with the current value of PCOUNT. This register is reset when either a count-match event occurs [PCOUNT = LIMIT] or PPB4 receives a sync. event. This result is available 1 SYSCLK cycle after the associated ADCPPB4RESULT is available. This will be 2 SYSCLK cycles after the associated ADCRESULT is available, unless multiple PPBs point to the same SOC [refer to the ADCPPB4RESULT timing information].
0x1F4 ADC_R_CFG_ADCPPB4PMIN 32-bit — ADC PPB4 Partial MIN Register.
  [31:17] SIGN — Sign Extended Bits. These bits reflect the same value as bit 16.
  [16:0] PMIN — Post Processing Block 4 Oversampling Partial Min. Each time a new result propagates through the PPB signal chain and latches into ADCPPB4RESULT the result replaces this register if it is smaller. This register is reset when either a count-match event occurs [PCOUNT = LIMIT] or PPB4 receives a sync. event. This result is available 1 SYSCLK cycle after the associated ADCPPB4RESULT is available. This will be 2 SYSCLK cycles after the associated ADCRESULT is available, unless multiple PPBs point to the same SOC [refer to the ADCPPB4RESULT timing information].
0x1F8 ADC_R_CFG_ADCPPB4PMINI — ADC PPB4 Partial Min Index Register.
  [9:0] PMINI — Post Processing Block 4 Oversampling Partial Index of Min. Each time a new result propagates through the PPB signal chain and latches into ADCPPB4RESULT if the result replaces PMIN this register is loaded with the current value of PCOUNT. This register is reset when either a count-match event occurs [PCOUNT = LIMIT] or PPB4 receives a sync. event. This result is available 1 SYSCLK cycle after the associated ADCPPB4RESULT is available. This will be 2 SYSCLK cycles after the associated ADCRESULT is available, unless multiple PPBs point to the same SOC [refer to the ADCPPB4RESULT timing information].
